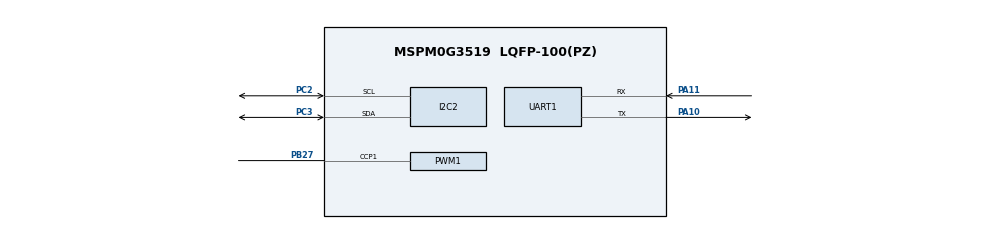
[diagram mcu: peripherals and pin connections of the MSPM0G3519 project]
// FSP on MSPM0, LP-MSPM0G3519: UART0 PA10/PA11 115200 (probe backchannel), I2C2 PC2 (SCL) / PC3 (SDA) 100 kHz,
// ADC0 sequence MEM4 to MEM7 = channels 0 to 3 on PA27, PA26, PA25, PA24 (nothing connected), started by an event (timer on channel 1), PWM TIMA1 CC1 on PB27 (1 kHz, 1000 counts), touch reset PB11 held high,
// user LED on PA0. 32 MHz SYSOSC. The GPT and ADC-with-timer examples use TIMG12 and TIMG0, which src/fsp_mspm0_gpt.c powers itself.
//@cliArgs --device "MSPM0G351X" --package "LQFP-100(PZ)" --part "Default"
//@v2CliArgs --device "MSPM0G3519" --package "LQFP-100(PZ)"
// @cliArgs --board /ti/boards/LP_MSPM0G3519 --rtos nortos
const Board  = scripting.addModule("/ti/driverlib/Board", {}, false);
const SYSCTL = scripting.addModule("/ti/driverlib/SYSCTL");
const GPIO   = scripting.addModule("/ti/driverlib/GPIO", {}, false);
const GB     = GPIO.addInstance();
const GL     = GPIO.addInstance();
const I2C    = scripting.addModule("/ti/driverlib/I2C", {}, false);
const I2C2   = I2C.addInstance();
const UART   = scripting.addModule("/ti/driverlib/UART", {}, false);
const UART1  = UART.addInstance();
const ADC12  = scripting.addModule("/ti/driverlib/ADC12", {}, false);
const ADC121 = ADC12.addInstance();
const PWM    = scripting.addModule("/ti/driverlib/PWM", {}, false);
const PWM1   = PWM.addInstance();

GB.$name = "PB";
GB.port  = "PORTB";
GB.associatedPins.create(1);
GB.associatedPins[0].$name = "TP_RST"; GB.associatedPins[0].assignedPin = "11"; GB.associatedPins[0].initialValue = "SET";

GL.$name = "LED";
GL.port  = "PORTA";
GL.associatedPins.create(1);
GL.associatedPins[0].$name = "RED"; GL.associatedPins[0].assignedPin = "0"; GL.associatedPins[0].initialValue = "CLEARED";

I2C2.$name                     = "TP_I2C";
I2C2.basicEnableController     = true;
I2C2.basicControllerBusSpeed   = 100000;
I2C2.intController             = ["TX_DONE","RX_DONE","NACK","ARBITRATION_LOST"];
I2C2.peripheral.$assign        = "I2C2";
I2C2.peripheral.sdaPin.$assign = "PC3";
I2C2.peripheral.sclPin.$assign = "PC2";

UART1.$name                    = "UART_0";
UART1.peripheral.$assign       = "UART0";
UART1.peripheral.rxPin.$assign = "PA11";
UART1.peripheral.txPin.$assign = "PA10";
UART1.targetBaudRate           = 115200;
UART1.enabledInterrupts        = ["RX"];

ADC121.$name                      = "ADC12_0";
ADC121.sampClkSrc                 = "DL_ADC12_CLOCK_SYSOSC";
ADC121.sampClkDiv                 = "DL_ADC12_CLOCK_DIVIDE_2";
ADC121.samplingOperationMode      = "sequence";
ADC121.repeatMode                 = true;     // stays armed after a sequence ...
ADC121.adcMem7trig                = "DL_ADC12_TRIGGER_MODE_TRIGGER_NEXT";   // ... and the next sequence waits for the next timer event
ADC121.startAdd                   = 4;
ADC121.endAdd                     = 7;
ADC121.trigSrc                    = "DL_ADC12_TRIG_SRC_EVENT";
ADC121.sampleTime0                = "1 us";
ADC121.adcMem4chansel             = "DL_ADC12_INPUT_CHAN_0";
ADC121.adcMem5chansel             = "DL_ADC12_INPUT_CHAN_1";
ADC121.adcMem6chansel             = "DL_ADC12_INPUT_CHAN_2";
ADC121.adcMem7chansel             = "DL_ADC12_INPUT_CHAN_3";
ADC121.adcMem4vref                = "VDDA";
ADC121.adcMem5vref                = "VDDA";
ADC121.adcMem6vref                = "VDDA";
ADC121.adcMem7vref                = "VDDA";
ADC121.peripheral.$assign         = "ADC0";
ADC121.peripheral.adcPin0.$assign = "PA27";
ADC121.peripheral.adcPin1.$assign = "PA26";
ADC121.peripheral.adcPin2.$assign = "PA25";
ADC121.peripheral.adcPin3.$assign = "PA24";

PWM1.$name                      = "PWM_0";
PWM1.clockPrescale              = 32;
PWM1.timerCount                 = 1000;
PWM1.peripheral.$assign         = "TIMA1";
PWM1.peripheral.ccp1Pin.$assign = "PB27";
PWM1.PWM_CHANNEL_1.$name        = "ti_driverlib_pwm_PWMTimerCC1";
PWM1.PWM_CHANNEL_1.dutyCycle    = 50;

SYSCTL.forceDefaultClkConfig = true;
SYSCTL.clockTreeEn           = true;
